# DSS0_DISPC_0_COMMON_M register map
Vendor: Texas Instruments
Peripheral module from a debugger description file (folder J721S2).
Registers are 32-bit, read-write, reset 0x0 unless marked. A register's access mark holds for its fields unless they carry their own. Offsets are as the file gives them; lines under a group give offsets from that group; [hi:lo] are bit positions; {n}, {i} and the like mark numbered series; 'fields as' and 'values as' point back to an identical list; <NAME> marks a mode.

## DSS0_DISPC_0_COMMON_M
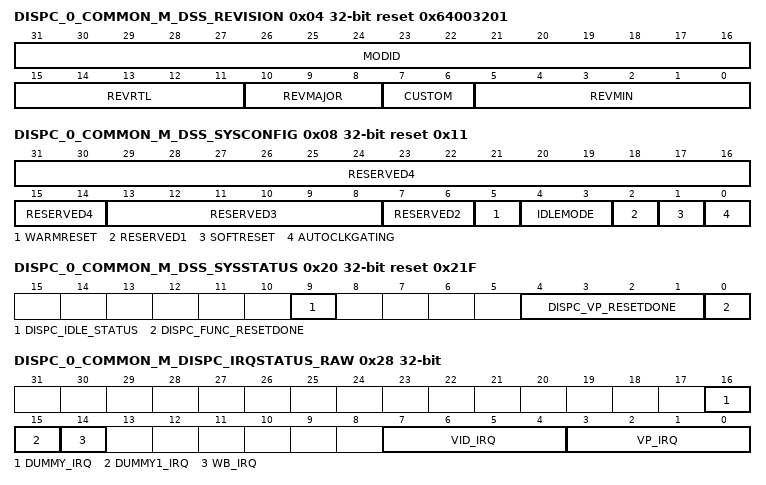
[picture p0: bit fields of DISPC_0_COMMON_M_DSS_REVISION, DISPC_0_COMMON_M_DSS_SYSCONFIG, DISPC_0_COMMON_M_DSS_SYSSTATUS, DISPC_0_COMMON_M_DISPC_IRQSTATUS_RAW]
0x04 DISPC_0_COMMON_M_DSS_REVISION ro reset 0x64003201 — This register contains the K3_DSS revision number
  [31:16] MODID — Module ID Field
  [15:11] REVRTL — RTL Revision
  [10:8] REVMAJOR — Major Revision
  [7:6] CUSTOM
  [5:0] REVMIN — Minor Revision
0x08 DISPC_0_COMMON_M_DSS_SYSCONFIG access per field reset 0x11 — This register controls various parameters related to software reset and IP idle
  [31:14] RESERVED4 ro — Write 0's for future compatibility. Read returns 0
  [13:8] RESERVED3 ro — Write 0's for future compatibility. Read returns 0
  [7:6] RESERVED2 ro — Write 0's for future compatibility. Read returns 0
  [5] WARMRESET rw — Warm reset. Setting this bit to 1 triggers a module warm reset. The bit is automatically reset by the hardware. During read, it always returns 0. The warm reset keeps the configuration registers unchanged
  [4:3] IDLEMODE rw — Deprecated
  [2] RESERVED1 ro — Write 0's for future compatibility. Read returns 0
  [1] SOFTRESET rw — Software reset. Setting this bit to 1 triggers a module reset. The bit is automatically reset by the hardware. During read, it always returns 0
  [0] AUTOCLKGATING rw — Internal clock gating strategy
0x20 DISPC_0_COMMON_M_DSS_SYSSTATUS ro reset 0x21F — This register provides status information about the module, excluding the interrupt status information
  [9] DISPC_IDLE_STATUS — Idle status of DISPC
  [4:1] DISPC_VP_RESETDONE — Reset status of VP[3:0] pixel clock domain
  [0] DISPC_FUNC_RESETDONE — Reset status of DISPC Functional clock domain
0x28 DISPC_0_COMMON_M_DISPC_IRQSTATUS_RAW access not given — RAW Interrupt status. Raw status is set even if interrupt is not enabled. Write 1 to set the RAW status
  [16] DUMMY_IRQ — Dummy IRQ STATUS- Reserved for future use (access R/W1TS)
  [15] DUMMY1_IRQ — Dummy IRQ STATUS- Reserved for future use (access R/W1TS)
  [14] WB_IRQ — WB IRQ STATUS. Register indicates the WB pipeline interrupt events if WB pipeline is present (access R/W1TS)
  [7:4] VID_IRQ — VID IRQ STATUS. Register indicates the Video pipeline[s] interrupt events. [0] -> VID1, [1] -> VIDL1, [2] -> VID2, [3] -> VIDL2 (access R/W1TS)
  [3:0] VP_IRQ — VP[3:0] IRQ STATUS. Register indicates the Video Port[s] interrupt events (access R/W1TS)
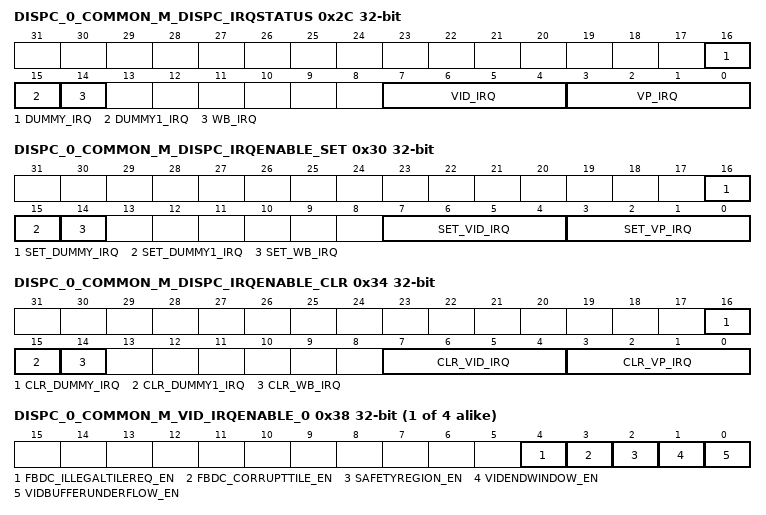
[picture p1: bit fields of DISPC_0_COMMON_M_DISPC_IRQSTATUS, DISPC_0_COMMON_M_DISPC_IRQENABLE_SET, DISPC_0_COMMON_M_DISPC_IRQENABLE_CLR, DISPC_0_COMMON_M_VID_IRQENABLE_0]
0x2C DISPC_0_COMMON_M_DISPC_IRQSTATUS access not given — Interrupt status. Enabled status, isn't set unless event is enabled. Write 1 to clear the status after interrupt has been serviced. RAW status also gets cleared, i.e. even if not enabled
  [16] DUMMY_IRQ — Dummy IRQ STATUS-Reserved for future use (access R/W1TC)
  [15] DUMMY1_IRQ — Dummy IRQ STATUS-Reserved for future use (access R/W1TC)
  [14] WB_IRQ — WB IRQ STATUS. Register indicates the WB pipeline interrupt events if WB pipeline is present (access R/W1TC)
  [7:4] VID_IRQ — VID IRQ STATUS. Register indicates the Video pipeline[s] interrupt events.[0] -> VID1, [1] -> VIDL1, [2] -> VID2, [3] -> VIDL2 (access R/W1TC)
  [3:0] VP_IRQ — VP[3:0] IRQ STATUS. Register indicates the Video Port[s] interrupt events (access R/W1TC)
0x30 DISPC_0_COMMON_M_DISPC_IRQENABLE_SET access not given — SET Interrupt enable. Write 1 to set interrupt enable. Readout equal to corresponding _CLR register
  [16] SET_DUMMY_IRQ — Dummy IRQ (access R/W1TS)
  [15] SET_DUMMY1_IRQ — Dummy IRQ (access R/W1TS)
  [14] SET_WB_IRQ — WB IRQ, if WB pipeline is present (access R/W1TS)
  [7:4] SET_VID_IRQ — VID IRQ. [0] -> VID1, [1] -> VIDL1, [2] -> VID2, [3] -> VIDL2 (access R/W1TS)
  [3:0] SET_VP_IRQ — VP[3:0] IRQ (access R/W1TS)
0x34 DISPC_0_COMMON_M_DISPC_IRQENABLE_CLR access not given — CLR Interrupt enable. Write 1 to clear interrupt enable
  [16] CLR_DUMMY_IRQ — Dummy IRQ (access R/W1TC)
  [15] CLR_DUMMY1_IRQ — Dummy IRQ (access R/W1TC)
  [14] CLR_WB_IRQ — WB IRQ, if WB pipeline is present (access R/W1TC)
  [7:4] CLR_VID_IRQ — VID IRQ.[0] -> VID1, [1] -> VIDL1, [2] -> VID2, [3] -> VIDL2 (access R/W1TC)
  [3:0] CLR_VP_IRQ — VP[3:0] IRQ (access R/W1TC)
{0x38+4i} DISPC_0_COMMON_M_VID_IRQENABLE_{i} (i=0..3) — This register allows to mask/unmask the VID internal sources of interrupt, on an event-by-event basis.[0] -> VID1, [1] -> VIDL1, [2] -> VID2, [3] -> VIDL2
  [4] FBDC_ILLEGALTILEREQ_EN — FBDC IRQ, Illegal tile req detected
  [3] FBDC_CORRUPTTILE_EN — FBDC IRQ. Corrupt tile detected
  [2] SAFETYREGION_EN — Safety Feature IRQ. This is raised when FrameFreeze is detected or data mismatch occurs within the safety region
  [1] VIDENDWINDOW_EN — Video End Window. This is raised by the DMA engine when the full video data has been sent to the pipeline
  [0] VIDBUFFERUNDERFLOW_EN — Video DMA Buffer Underflow. This is raised when the DMA buffer does not have the data requested by the Video pipeline
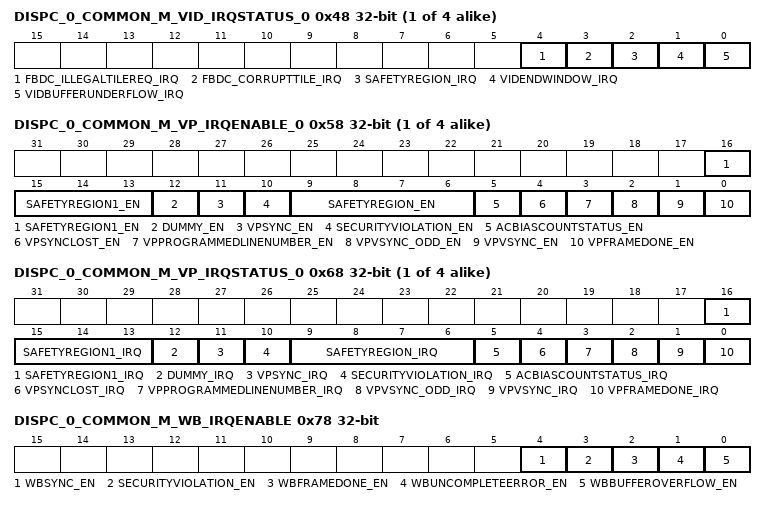
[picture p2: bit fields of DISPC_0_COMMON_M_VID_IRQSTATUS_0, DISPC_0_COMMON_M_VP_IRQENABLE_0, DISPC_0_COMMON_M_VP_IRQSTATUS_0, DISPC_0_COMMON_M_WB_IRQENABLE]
{0x48+4i} DISPC_0_COMMON_M_VID_IRQSTATUS_{i} access not given (i=0..3) — This register groups all the status of the VID internal events that generate an interrupt. Write 1 to a clear a bit field.[0] -> VID1, [1] -> VIDL1, [2] -> VID2, [3] -> VIDL2
  [4] FBDC_ILLEGALTILEREQ_IRQ — FBDC IRQ, Illegal tile req detected (access R/W1TC)
  [3] FBDC_CORRUPTTILE_IRQ — FBDC IRQ. Corrupt tile detected (access R/W1TC)
  [2] SAFETYREGION_IRQ — Safety Feature IRQ. This is raised when FrameFreeze is detected or data mismatch occurs within the safety region (access R/W1TC)
  [1] VIDENDWINDOW_IRQ — Video End Window. This is raised by the DMA engine when the full video data has been sent to the pipeline (access R/W1TC)
  [0] VIDBUFFERUNDERFLOW_IRQ — Video DMA Buffer Underflow. This is raised when the DMA buffer does not have the data requested by the Video pipeline (access R/W1TC)
{0x58+4i} DISPC_0_COMMON_M_VP_IRQENABLE_{i} (i=0..3) — This register allows to mask/unmask the VP_{i} internal sources of interrupt, on an event-by-event basis
  [16:13] SAFETYREGION1_EN — Safety Feature IRQ. This is raised when FrameFreeze is detected or data mismatch occurs within the safety region 4-7
  [12] DUMMY_EN — Dummy IRQ for future use
  [11] VPSYNC_EN — Go bit clear event
  [10] SECURITYVIOLATION_EN — Security Violation interrupt for OVR/VP. Non-secure OVR/VP connected to secure VID
  [9:6] SAFETYREGION_EN — Safety Feature IRQ. This is raised when FrameFreeze is detected or data mismatch occurs within the safety region 0-3
  [5] ACBIASCOUNTSTATUS_EN — AC BIAS transition counter has decremented to zero
  [4] VPSYNCLOST_EN — Synchronization Lost for Video Port
  [3] VPPROGRAMMEDLINENUMBER_EN — Programmed Line Number. It indicates that the scan of the display has reached the programmed user line number
  [2] VPVSYNC_ODD_EN — VSYNC for odd field from interlace mode only
  [1] VPVSYNC_EN — Vertical Synchronization for VP
  [0] VPFRAMEDONE_EN — Frame Done for Video Port. VP output has been disabled by user. All the data have been sent
{0x68+4i} DISPC_0_COMMON_M_VP_IRQSTATUS_{i} access not given (i=0..3) — This register groups all the status of the VP_{i} internal events that generate an interrupt. Write 1 to a given bit resets this bit
  [16:13] SAFETYREGION1_IRQ — Safety Feature IRQ. This is raised when FrameFreeze is detected or data mismatch occurs within the safety region 4-7 (access R/W1TC)
  [12] DUMMY_IRQ — Dummy IRQ for future use (access R/W1TC)
  [11] VPSYNC_IRQ — Go bit clear event (access R/W1TC)
  [10] SECURITYVIOLATION_IRQ — Security Violation IRQ. Non-secure OVR/VP connected to secure VID (access R/W1TC)
  [9:6] SAFETYREGION_IRQ — Safety Feature IRQ. This is raised when FrameFreeze is detected or data mismatch occurs within the safety region 0-3 (access R/W1TC)
  [5] ACBIASCOUNTSTATUS_IRQ — AC BIAS transition counter has decremented to zero (access R/W1TC)
  [4] VPSYNCLOST_IRQ — Synchronization Lost on VP output. The required data are not output at the correct time due to too short blanking periods or stall of at least one pipelines associated with VP output (access R/W1TC)
  [3] VPPROGRAMMEDLINENUMBER_IRQ — Programmed Line Number. It indicates that the scan of the display has reached the programmed user line number (access R/W1TC)
  [2] VPVSYNC_ODD_IRQ — VSYNC for odd field. For interlace mode only (access R/W1TC)
  [1] VPVSYNC_IRQ — Vertical Synchronization for VP output. It is used as VSYNC_EVEN in case of interlace mode (access R/W1TC)
  [0] VPFRAMEDONE_IRQ — Frame Done for VP. VP output has been disabled by user All the data have been sent (access R/W1TC)
0x78 DISPC_0_COMMON_M_WB_IRQENABLE — This register allows to mask/unmask the WB internal sources of interrupt, if WB pipeline is present, on an event-by-event basis
  [4] WBSYNC_EN — Write-back sync IRQ. Configuration copied from shadow to work for WB for next frame
  [3] SECURITYVIOLATION_EN — Security Violation IRQ. Non-secure WB connected to a secure VID/OVR
  [2] WBFRAMEDONE_EN — Write-back Frame Done
  [1] WBUNCOMPLETEERROR_EN — The write back buffer has been flushed before been fully drained. Can only occur in WB Capture Mode use-case
  [0] WBBUFFEROVERFLOW_EN — Write-back DMA Buffer Overflow. Can only occur in WB Capture Mode use-case
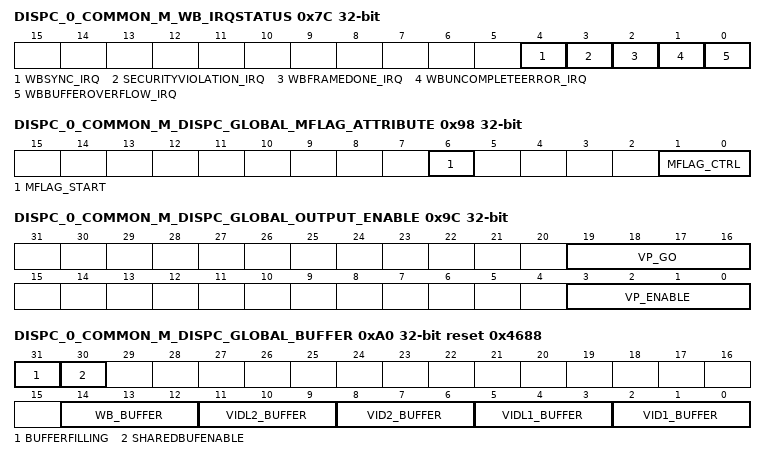
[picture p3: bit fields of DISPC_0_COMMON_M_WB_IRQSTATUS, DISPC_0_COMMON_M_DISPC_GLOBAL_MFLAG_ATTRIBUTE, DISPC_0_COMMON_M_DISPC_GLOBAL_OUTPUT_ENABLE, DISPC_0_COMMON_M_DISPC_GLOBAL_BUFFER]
0x7C DISPC_0_COMMON_M_WB_IRQSTATUS access not given — This register groups all the status of the WB internal events that generate an interrupt, if WB pipeline is present. Write 1 to a given bit resets this bit
  [4] WBSYNC_IRQ — Write-back sync IRQ. Configuration copied from shadow to work for WB for next frame (access R/W1TC)
  [3] SECURITYVIOLATION_IRQ — Security Violation IRQ. Non-secure WB connected to a secure VID/OVR (access R/W1TC)
  [2] WBFRAMEDONE_IRQ — Write-back Frame Done (access R/W1TC)
  [1] WBUNCOMPLETEERROR_IRQ — Write back DMA buffer is flushed before been completely drained. Can only occur in WB Capture Mode use-case (access R/W1TC)
  [0] WBBUFFEROVERFLOW_IRQ — Write-back DMA Buffer Overflow The DMA buffer is full (access R/W1TC)
0x80 DISPC_0_COMMON_M_DISPC_IRQ_EOI_FUNC wo — End-Of-Interrupt register for FUNC interrupts, to be used if pulse interrupts are used
  [0] EOI — Write 1 to acknowledge a pulse IRQ
0x84 DISPC_0_COMMON_M_DISPC_IRQ_EOI_SAFETY wo — End-Of-Interrupt register for SAFETY interrupts, to be used if pulse interrupts are used
  [0] EOI — Write 1 to acknowledge a pulse IRQ
0x88 DISPC_0_COMMON_M_DISPC_IRQ_EOI_SECURITY wo — End-Of-Interrupt register for SECURITY interrupts, to be used if pulse interrupts are used
  [0] EOI — Write 1 to acknowledge a pulse IRQ
0x90 DISPC_0_COMMON_M_DISPC_SECURE_DISABLE — Disable security settings throughout DSS IP. COMMON_1.DISPC_SECURE bits are honoured only if COMMON.DISPC_SECURE_DISABLE =0
  [0] SECURE_DISABLE — Secure disable bit
0x98 DISPC_0_COMMON_M_DISPC_GLOBAL_MFLAG_ATTRIBUTE — MFLAG control register
  [6] MFLAG_START — MFLAG_START for DMA master port
  [1:0] MFLAG_CTRL — MFLAG_CTRL for DMA master port
0x9C DISPC_0_COMMON_M_DISPC_GLOBAL_OUTPUT_ENABLE — DISPC global output enable register. The ENABLE or GO bit for a particular output port is set when either the corresponding bit in this register is set or the corresponding bit within the sub-module is set. This register allows enabling multiple outputs synchronously [simultaneously], which is not possible if the ENABLE/GO bits are present only within the sub-module
  [19:16] VP_GO — Global GO Command for the VP[3:0] output. It is used to synchronize the pipelines associated with the VP output. wr: immediate
  [3:0] VP_ENABLE — Global VP[3:0] Enable
0xA0 DISPC_0_COMMON_M_DISPC_GLOBAL_BUFFER reset 0x4688 — The register configures the DMA buffers allocations to the pipelines for DMA
  [31] BUFFERFILLING — Controls if the DMA buffers are re-filled only when the LOW threshold is reached or if all DMA buffers are re-filled when at least one of them reaches the LOW threshold
  [30] SHAREDBUFENABLE — Enable Shared DMA Buffer feature
  [14:12] WB_BUFFER — WB DMA buffer allocation to one of the pipelines, if WB pipeline is present
  [11:9] VIDL2_BUFFER — VIDL2 DMA buffer allocation to one of the pipelines, if VIDL2 is present
  [8:6] VID2_BUFFER — VID2 DMA buffer allocation to one of the pipelines, if VID2 is present
  [5:3] VIDL1_BUFFER — VIDL1 DMA buffer allocation to one of the pipelines
  [2:0] VID1_BUFFER — VID1 DMA buffer allocation to one of the pipelines
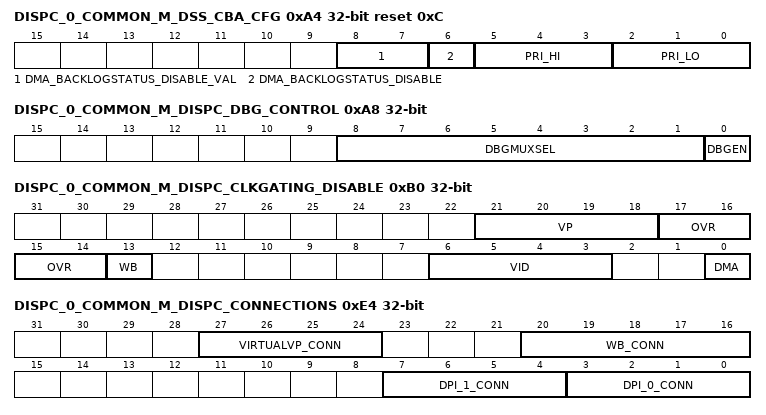
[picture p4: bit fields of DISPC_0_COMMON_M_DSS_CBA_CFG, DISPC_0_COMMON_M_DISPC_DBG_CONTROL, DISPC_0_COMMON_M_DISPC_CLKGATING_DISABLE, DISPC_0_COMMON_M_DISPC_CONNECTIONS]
0xA4 DISPC_0_COMMON_M_DSS_CBA_CFG reset 0xC — This register contains CBA specific config bits in DSS
  [8:7] DMA_BACKLOGSTATUS_DISABLE_VAL — IP Internal - Tie-off value on DMA_BACKLOGSTATUS pins when DMA Backlog Status reporting is disabled
  [6] DMA_BACKLOGSTATUS_DISABLE — IP Internal - Disable generation of DMA Backlog Status reporting to interconnect
  [5:3] PRI_HI — The value sent out on the PRI_HI bus from DSS to CBA Indicates the priority level for high-priority [MFLAG] transactions. Value of 0x0 indicates highest priority Value of 0x7 indicates lowest priority
  [2:0] PRI_LO — The value sent out on the PRI_LO bus from DSS to CBA Indicates the priority level for normal [non-MFLAG] transactions. Value of 0x0 indicates highest priority Value of 0x7 indicates lowest priority
0xA8 DISPC_0_COMMON_M_DISPC_DBG_CONTROL — DISPC debug status control register
  [8:1] DBGMUXSEL — Mux select for the debug status
  [0] DBGEN — Enable debug ports
0xAC DISPC_0_COMMON_M_DISPC_DBG_STATUS ro — DISPC debug status register
  [31:0] DBGOUT — Debug status
0xB0 DISPC_0_COMMON_M_DISPC_CLKGATING_DISABLE — Register to control clock gating at DISPC sub-module level
  [21:18] VP — Clock gating control for VP[3:0]
  [17:14] OVR — Clock gating control for OVR[3:0]
  [13] WB — Clock gating control for WB, if WB pipeline is present
  [6:3] VID — Clock gating control for VID. [0] -> VID1, [1] -> VIDL1, [2] -> VID2, [3] -> VIDL2
  [0] DMA — Clock gating control for DMA
0xB8 DISPC_0_COMMON_M_FBDC_REVISION_1 ro — This register contains the FBDC Product Code
  [15:0] PRODUCTCODE — FBDC Product Code
0xBC DISPC_0_COMMON_M_FBDC_REVISION_2 ro — This register contains the FBDC Branch Code
  [15:0] BRANCHCODE — FBDC Branch Code
0xC0 DISPC_0_COMMON_M_FBDC_REVISION_3 ro — This register contains the FBDC Version Code
  [15:0] VERSIONCODE — FBDC Version Code
0xC4 DISPC_0_COMMON_M_FBDC_REVISION_4 ro — This register contains the FBDC Scalable Core Code
  [15:0] CORECODE — FBDC Scalable Core Code
0xC8 DISPC_0_COMMON_M_FBDC_REVISION_5 ro — This register contains the FBDC Configuration Code
  [15:0] CONFIGCODE — FBDC Configuration Code
0xCC DISPC_0_COMMON_M_FBDC_REVISION_6 ro — This register contains the FBDC Changelist Code
  [31:0] CHANGELISTCODE — FBDC Changelist Code
0xD0 DISPC_0_COMMON_M_FBDC_COMMON_CONTROL — This register contains the common control signals for FBDC
  [2] GPUTYPE — GPU Selection
0xD4 DISPC_0_COMMON_M_FBDC_CONSTANT_COLOR_0 — Defines the Constant Color-0 value to be used for the FBDC
  [31:0] CONSTCOLOR
0xD8 DISPC_0_COMMON_M_FBDC_CONSTANT_COLOR_1 — Defines the Constant Color-1 value to be used for the FBDC
  [31:0] CONSTCOLOR
0xE4 DISPC_0_COMMON_M_DISPC_CONNECTIONS — Connections of various sub-modules within DISPC, as well as some peripherals outside. One hot encoding
  [27:24] VIRTUALVP_CONN — Defines the connection to VIRTUAL_VP output
  [20:16] WB_CONN — Defines the connection to WB pipe
  [7:4] DPI_1_CONN — Defines the connection to DPI-1 output. For J7, valid values are 0x0, 0x2 and 0x8
  [3:0] DPI_0_CONN — Defines the connection to DPI-0 output. For J7, valid values are 0x0, 0x2 and 0x8
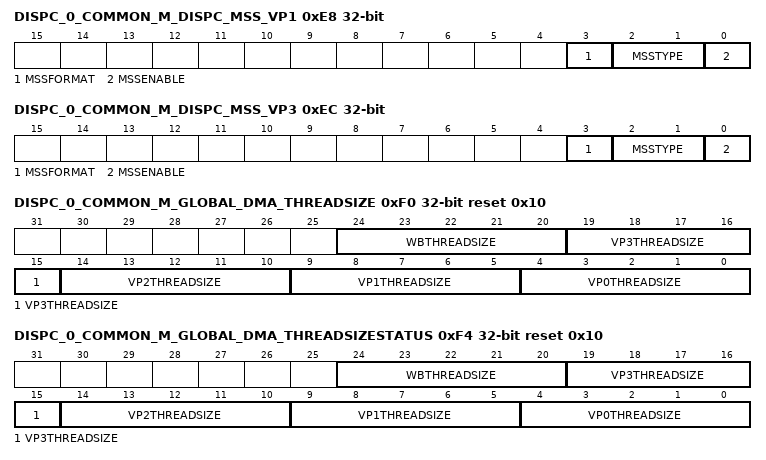
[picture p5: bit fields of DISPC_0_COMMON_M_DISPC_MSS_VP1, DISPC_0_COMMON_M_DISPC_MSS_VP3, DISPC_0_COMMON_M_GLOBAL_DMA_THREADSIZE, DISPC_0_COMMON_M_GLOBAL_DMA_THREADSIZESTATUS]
0xE8 DISPC_0_COMMON_M_DISPC_MSS_VP1 — This register controls the Merge_Split_Sync operation for VP1
  [3] MSSFORMAT — Merge Split format
  [2:1] MSSTYPE — Merge-Split-Sync operation type
  [0] MSSENABLE — Merge-Split-Sync operation Enable
0xEC DISPC_0_COMMON_M_DISPC_MSS_VP3 — This register controls the Merge_Split_Sync operation for VP3
  fields as DISPC_0_COMMON_M_DISPC_MSS_VP1
0xF0 DISPC_0_COMMON_M_GLOBAL_DMA_THREADSIZE reset 0x10 — This register configures the DMA buffer size allocated to the different threads - Shared memory feature
  [24:20] WBTHREADSIZE — Total DMA buffer size for all the pipelines connected to WB THREAD4.If the value programmed is n, then the allocated buffer size is 16KB*n. Default:0KB
  [19:15] VP3THREADSIZE — Total DMA buffer size for all the pipelines connected to VP3 THREAD3.If the value programmed is n, then the allocated buffer size is 16KB*n. Default:0KB
  [14:10] VP2THREADSIZE — Total DMA buffer size for all the pipelines connected to VP2 THREAD2.If the value programmed is n, then the allocated buffer size is 16KB*n. Default:0KB
  [9:5] VP1THREADSIZE — Total DMA buffer size for all the pipelines connected to VP1 THREAD1.If the value programmed is n, then the allocated buffer size is 16KB*n. Default:0KB
  [4:0] VP0THREADSIZE — Total DMA buffer size for all the pipelines connected to VP0 THREAD0.If the value programmed is n, then the allocated buffer size is 16KB*n. Default:256KB
0xF4 DISPC_0_COMMON_M_GLOBAL_DMA_THREADSIZESTATUS ro reset 0x10 — This register read the synchronized value of DMA buffer size allocated to the different threads - Shared memory feature
  [24:20] WBTHREADSIZE — Synchronized version of WB THREADSIZE. Value used by HW
  [5n+4:5n] VP{n}THREADSIZE (n=0..3) — Synchronized version of VP{n} THREADSIZE. Value used by HW
0xF8 DISPC_0_COMMON_M_GLOBAL_GOBITMODE — GLOBAL_GOBITMODE settings
  [0] MODE — Go bit
